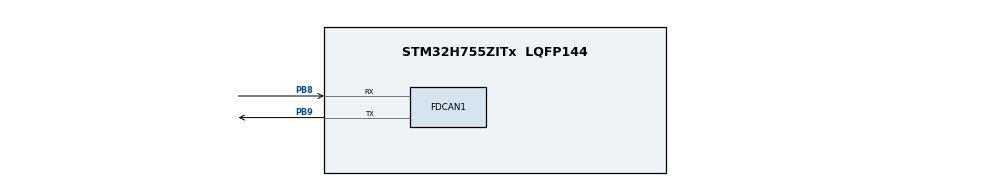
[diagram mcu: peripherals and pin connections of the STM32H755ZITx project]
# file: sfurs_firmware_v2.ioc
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CortexM4.IPs=CORTEX_M4\:I,FATFS_M4\:I,FREERTOS_M4\:I,IWDG2\:I,OPENAMP_M4\:I,PDM2PCM_M4\:I,PWR,RCC,RESMGR_UTILITY,SYS_M4\:I,USB_DEVICE_M4\:I,USB_HOST_M4\:I,VREFBUF,WWDG2\:I,GPIO,DMA,BDMA,MDMA,NVIC2\:I
CortexM7.IPs=CORTEX_M7\:I,FATFS_M7\:I,FREERTOS_M7\:I,IWDG1\:I,OPENAMP_M7\:I,PDM2PCM_M7\:I,PWR\:I,RCC\:I,RESMGR_UTILITY\:I,SYS\:I,USB_DEVICE_M7\:I,USB_HOST_M7\:I,VREFBUF\:I,WWDG1\:I,GPIO\:I,DMA\:I,BDMA\:I,MDMA\:I,NVIC1\:I,FDCAN1\:I
FDCAN1.CalculateBaudRateNominal=500000
FDCAN1.CalculateTimeBitNominal=2000
FDCAN1.CalculateTimeQuantumNominal=100.0
FDCAN1.FrameFormat=FDCAN_FRAME_FD_NO_BRS
FDCAN1.Mode=FDCAN_MODE_NORMAL
FDCAN1.AutoRetransmission=DISABLE
FDCAN1.NominalPrescaler=4
FDCAN1.NominalSyncJumpWidth=2
FDCAN1.NominalTimeSeg1=17
FDCAN1.NominalTimeSeg2=2
FDCAN1.DataPrescaler=4
FDCAN1.DataSyncJumpWidth=2
FDCAN1.DataTimeSeg1=17
FDCAN1.DataTimeSeg2=2
FDCAN1.RxFifo0ElmtsNbr=8
FDCAN1.RxFifo0ElmtSize=FDCAN_DATA_BYTES_64
FDCAN1.TxFifoQueueElmtsNbr=8
FDCAN1.TxElmtSize=FDCAN_DATA_BYTES_64
Mcu.Family=STM32H7
Mcu.Name=STM32H755ZITx
Mcu.Package=LQFP144
NVIC1.PriorityGroup=NVIC_PRIORITYGROUP_4
NVIC2.PriorityGroup=NVIC_PRIORITYGROUP_4
PB8.Mode=FDCAN_Activate
PB8.PinAttribute=CortexM7
PB8.Signal=FDCAN1_RX
PB9.Mode=FDCAN_Activate
PB9.PinAttribute=CortexM7
PB9.Signal=FDCAN1_TX
ProjectManager.HeapSize=M4-0x200,M7-0x200
ProjectManager.StackSize=M4-0x400,M7-0x400
ProjectManager.TargetToolchain=CMake
RCC.ADCFreq_Value=129000000
RCC.APB1Freq_Value=64000000
RCC.APB2Freq_Value=64000000
RCC.APB3Freq_Value=64000000
RCC.APB4Freq_Value=64000000
RCC.CortexFreq_Value=64000000
RCC.DIVQ1=8
RCC.HCLKFreq_Value=64000000
RCC.SYSCLKFreq_VALUE=64000000
RCC.USBFreq_Value=129000000
RCC.PLLM=4
RCC.PLLN=20
SYS.userName=SYS_M7
VP_SYS_M4_VS_Systick.Mode=SysTick
board=custom

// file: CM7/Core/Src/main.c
/* USER CODE BEGIN Header */
/**
  ******************************************************************************
  * @file           : main.c
  * @brief          : Main program body
  ******************************************************************************
  * @attention
  *
  * Copyright (c) 2026 STMicroelectronics.
  * All rights reserved.
  *
  * This software is licensed under terms that can be found in the LICENSE file
  * in the root directory of this software component.
  * If no LICENSE file comes with this software, it is provided AS-IS.
  *
  ******************************************************************************
  */
/* USER CODE END Header */
#include "main.h"

/* USER CODE BEGIN PD */
/* NUCLEO-H755ZI-Q LD1: green, active high, PB0. */

/* DUAL_CORE_BOOT_SYNC_SEQUENCE: Define for dual core boot synchronization    */
/*                             demonstration code based on hardware semaphore */
/* This define is present in both CM7/CM4 projects                            */
/* To comment when developping/debugging on a single core                     */

// Only Running CM7 for now.
// #define DUAL_CORE_BOOT_SYNC_SEQUENCE

#if defined(DUAL_CORE_BOOT_SYNC_SEQUENCE)
#ifndef HSEM_ID_0
#define HSEM_ID_0 (0U) /* HW semaphore 0*/
#endif
#endif /* DUAL_CORE_BOOT_SYNC_SEQUENCE */

/* USER CODE END PD */

FDCAN_HandleTypeDef hfdcan1;

void SystemClock_Config(void);
static void MX_GPIO_Init(void);
static void MX_FDCAN1_Init(void);

/* USER CODE BEGIN 0 */
static void led_init(void)
{
  GPIO_InitTypeDef led = {0};
  __HAL_RCC_GPIOB_CLK_ENABLE();
  HAL_GPIO_WritePin(GPIOB, GPIO_PIN_0, GPIO_PIN_RESET);
  led.Pin = GPIO_PIN_0;
  led.Mode = GPIO_MODE_OUTPUT_PP;
  led.Pull = GPIO_NOPULL;
  led.Speed = GPIO_SPEED_FREQ_LOW;
  HAL_GPIO_Init(GPIOB, &led);
}
/* USER CODE END 0 */

int main(void)
{

  /* USER CODE BEGIN 1 */
  uint32_t alive_tick = 0;
  /* USER CODE END 1 */
/* USER CODE BEGIN Boot_Mode_Sequence_0 */
#if defined(DUAL_CORE_BOOT_SYNC_SEQUENCE)
  int32_t timeout;
#endif /* DUAL_CORE_BOOT_SYNC_SEQUENCE */
/* USER CODE END Boot_Mode_Sequence_0 */

/* USER CODE BEGIN Boot_Mode_Sequence_1 */
#if defined(DUAL_CORE_BOOT_SYNC_SEQUENCE)
  /* Wait until CPU2 boots and enters in stop mode or timeout*/
  timeout = 0xFFFF;
  while((__HAL_RCC_GET_FLAG(RCC_FLAG_D2CKRDY) != RESET) && (timeout-- > 0));
  if ( timeout < 0 )
  {
  Error_Handler();
  }
#endif /* DUAL_CORE_BOOT_SYNC_SEQUENCE */
/* USER CODE END Boot_Mode_Sequence_1 */
  /* MCU Configuration--------------------------------------------------------*/

  /* Reset of all peripherals, Initializes the Flash interface and the Systick. */
  HAL_Init();

  /* Configure the system clock */
  SystemClock_Config();
/* USER CODE BEGIN Boot_Mode_Sequence_2 */
#if defined(DUAL_CORE_BOOT_SYNC_SEQUENCE)
/* When system initialization is finished, Cortex-M7 will release Cortex-M4 by means of
HSEM notification */
/*HW semaphore Clock enable*/
__HAL_RCC_HSEM_CLK_ENABLE();
/*Take HSEM */
HAL_HSEM_FastTake(HSEM_ID_0);
/*Release HSEM in order to notify the CPU2(CM4)*/
HAL_HSEM_Release(HSEM_ID_0,0);
/* wait until CPU2 wakes up from stop mode */
timeout = 0xFFFF;
while((__HAL_RCC_GET_FLAG(RCC_FLAG_D2CKRDY) == RESET) && (timeout-- > 0));
if ( timeout < 0 )
{
Error_Handler();
}
#endif /* DUAL_CORE_BOOT_SYNC_SEQUENCE */
/* USER CODE END Boot_Mode_Sequence_2 */

  /* Initialize all configured peripherals */
  MX_GPIO_Init();
  MX_FDCAN1_Init();
  /* USER CODE BEGIN 2 */
  led_init();
  /* USER CODE END 2 */

  /* Infinite loop */
  while (1)
  {

    /* USER CODE BEGIN 3 */
    if ((uint32_t)(HAL_GetTick() - alive_tick) >= 500U) {
      HAL_GPIO_TogglePin(GPIOB, GPIO_PIN_0);
      alive_tick = HAL_GetTick();
    }
  }
  /* USER CODE END 3 */
}

void SystemClock_Config(void)
{
  RCC_OscInitTypeDef RCC_OscInitStruct = {0};
  RCC_ClkInitTypeDef RCC_ClkInitStruct = {0};

  /** Supply configuration update enable
  */
  HAL_PWREx_ConfigSupply(PWR_DIRECT_SMPS_SUPPLY);

  /** Configure the main internal regulator output voltage
  */
  __HAL_PWR_VOLTAGESCALING_CONFIG(PWR_REGULATOR_VOLTAGE_SCALE3);

  while(!__HAL_PWR_GET_FLAG(PWR_FLAG_VOSRDY)) {}

  /** Initializes the RCC Oscillators according to the specified parameters
  * in the RCC_OscInitTypeDef structure.
  */
  RCC_OscInitStruct.OscillatorType = RCC_OSCILLATORTYPE_HSI;
  RCC_OscInitStruct.HSIState = RCC_HSI_DIV1;
  RCC_OscInitStruct.HSICalibrationValue = RCC_HSICALIBRATION_DEFAULT;
  RCC_OscInitStruct.PLL.PLLState = RCC_PLL_ON;
  RCC_OscInitStruct.PLL.PLLSource = RCC_PLLSOURCE_HSI;
   /* HSI 64 MHz / 4 * 20 / 8 = 40 MHz on PLL1Q (FDCAN). */
   RCC_OscInitStruct.PLL.PLLM = 4;
   RCC_OscInitStruct.PLL.PLLN = 20;
  RCC_OscInitStruct.PLL.PLLP = 2;
   RCC_OscInitStruct.PLL.PLLQ = 8;
  RCC_OscInitStruct.PLL.PLLR = 2;
   RCC_OscInitStruct.PLL.PLLRGE = RCC_PLL1VCIRANGE_3;
  RCC_OscInitStruct.PLL.PLLVCOSEL = RCC_PLL1VCOWIDE;
  RCC_OscInitStruct.PLL.PLLFRACN = 0;
  if (HAL_RCC_OscConfig(&RCC_OscInitStruct) != HAL_OK)
  {
    Error_Handler();
  }

  /** Initializes the CPU, AHB and APB buses clocks
  */
  RCC_ClkInitStruct.ClockType = RCC_CLOCKTYPE_HCLK|RCC_CLOCKTYPE_SYSCLK
                              |RCC_CLOCKTYPE_PCLK1|RCC_CLOCKTYPE_PCLK2
                              |RCC_CLOCKTYPE_D3PCLK1|RCC_CLOCKTYPE_D1PCLK1;
  RCC_ClkInitStruct.SYSCLKSource = RCC_SYSCLKSOURCE_HSI;
  RCC_ClkInitStruct.SYSCLKDivider = RCC_SYSCLK_DIV1;
  RCC_ClkInitStruct.AHBCLKDivider = RCC_HCLK_DIV1;
  RCC_ClkInitStruct.APB3CLKDivider = RCC_APB3_DIV1;
  RCC_ClkInitStruct.APB1CLKDivider = RCC_APB1_DIV1;
  RCC_ClkInitStruct.APB2CLKDivider = RCC_APB2_DIV1;
  RCC_ClkInitStruct.APB4CLKDivider = RCC_APB4_DIV1;

  if (HAL_RCC_ClockConfig(&RCC_ClkInitStruct, FLASH_LATENCY_1) != HAL_OK)
  {
    Error_Handler();
  }
}

static void MX_FDCAN1_Init(void)
{

  hfdcan1.Instance = FDCAN1;
   hfdcan1.Init.FrameFormat = FDCAN_FRAME_FD_NO_BRS;
  hfdcan1.Init.Mode = FDCAN_MODE_NORMAL;
  hfdcan1.Init.AutoRetransmission = DISABLE;
  hfdcan1.Init.TransmitPause = DISABLE;
  hfdcan1.Init.ProtocolException = DISABLE;
   hfdcan1.Init.NominalPrescaler = 4;
   hfdcan1.Init.NominalSyncJumpWidth = 2;
   hfdcan1.Init.NominalTimeSeg1 = 17;
   hfdcan1.Init.NominalTimeSeg2 = 2;
   /* BRS is disabled; keep data timing valid and equal to nominal timing. */
   hfdcan1.Init.DataPrescaler = 4;
   hfdcan1.Init.DataSyncJumpWidth = 2;
   hfdcan1.Init.DataTimeSeg1 = 17;
   hfdcan1.Init.DataTimeSeg2 = 2;
  hfdcan1.Init.MessageRAMOffset = 0;
  hfdcan1.Init.StdFiltersNbr = 0;
  hfdcan1.Init.ExtFiltersNbr = 0;
   hfdcan1.Init.RxFifo0ElmtsNbr = 8;
   hfdcan1.Init.RxFifo0ElmtSize = FDCAN_DATA_BYTES_64;
  hfdcan1.Init.RxFifo1ElmtsNbr = 0;
  hfdcan1.Init.RxFifo1ElmtSize = FDCAN_DATA_BYTES_8;
  hfdcan1.Init.RxBuffersNbr = 0;
  hfdcan1.Init.RxBufferSize = FDCAN_DATA_BYTES_8;
  hfdcan1.Init.TxEventsNbr = 0;
  hfdcan1.Init.TxBuffersNbr = 0;
   hfdcan1.Init.TxFifoQueueElmtsNbr = 8;
  hfdcan1.Init.TxFifoQueueMode = FDCAN_TX_FIFO_OPERATION;
   hfdcan1.Init.TxElmtSize = FDCAN_DATA_BYTES_64;
  if (HAL_FDCAN_Init(&hfdcan1) != HAL_OK)
  {
    Error_Handler();
  }

}

static void MX_GPIO_Init(void)
{

  /* GPIO Ports Clock Enable */
  __HAL_RCC_GPIOA_CLK_ENABLE();

}

void Error_Handler(void)
{
  __disable_irq();
  while (1)
  {
  }
}
